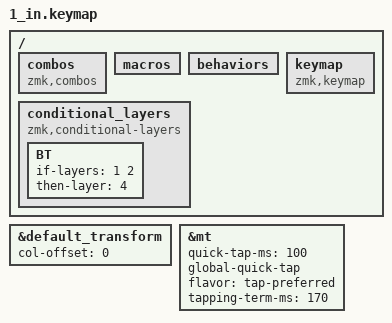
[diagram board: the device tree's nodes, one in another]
#include "keys_de_swiss.h"
#include <behaviors.dtsi>
#include <dt-bindings/zmk/bt.h>
#include <dt-bindings/zmk/keys.h>
#include <dt-bindings/zmk/outputs.h>

&default_transform { col-offset = <0>; };

#define BASE 0
#define NAV  1
#define SYM  2
#define ADJ  3

&mt {
    quick-tap-ms = <100>;
    global-quick-tap;
    flavor = "tap-preferred";
    tapping-term-ms = <170>;
};

/ {
    combos {
        compatible = "zmk,combos";

        // BEGIN combos
        // END combos
    };

    macros {
        // BEGIN macros
        // END macros
    };

    behaviors {
        // BEGIN behaviors
        // END behaviors
    };

    keymap {
        compatible = "zmk,keymap";


        // BEGIN keymap
        // END keymap
    };

    conditional_layers {
        compatible = "zmk,conditional-layers";

        BT {
            if-layers = <1 2>;
            then-layer = <4>;
        };
    };
};
